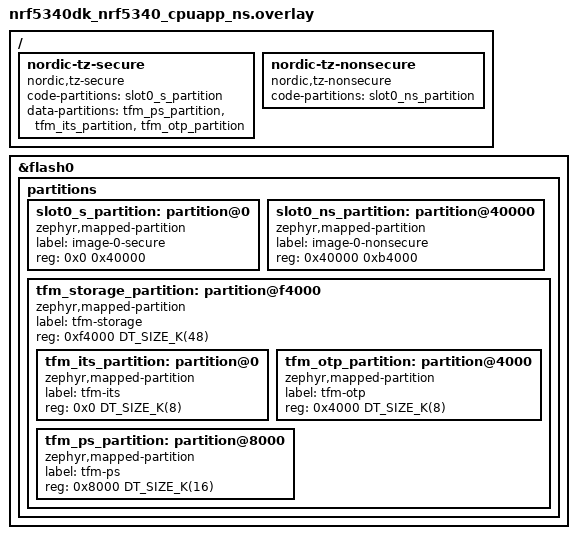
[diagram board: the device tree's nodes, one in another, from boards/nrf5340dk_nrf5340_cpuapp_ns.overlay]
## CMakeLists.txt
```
#
# Copyright (c) 2021 Nordic Semiconductor ASA
#
# SPDX-License-Identifier: LicenseRef-Nordic-5-Clause
#

cmake_minimum_required(VERSION 3.20.0)

find_package(Zephyr REQUIRED HINTS $ENV{ZEPHYR_BASE})
project(NONE)

FILE(GLOB app_sources src/*.c)
target_sources(app PRIVATE ${app_sources})

if(DEFINED CONFIG_SOC_NRF9160)
  set(family_arg NRF91)
else()
  set(family_arg NRF53)
endif()


if("${CONFIG_HUK_TEST_BOARD_SNR}" STREQUAL "")
  message(WARNING "If it is to be run on target, this test requires setting "
    "CONFIG_HUK_TEST_BOARD_SNR")
else()
  add_custom_command(TARGET app
    POST_BUILD
    COMMAND
    ${PYTHON_EXECUTABLE}
    ${CMAKE_CURRENT_LIST_DIR}/write_kmu.py
    --family ${family_arg}
    --snr ${CONFIG_HUK_TEST_BOARD_SNR}
    )
endif()
```

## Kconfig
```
#
# Copyright (c) 2021 Nordic Semiconductor
#
# SPDX-License-Identifier: LicenseRef-Nordic-5-Clause
#

source "Kconfig.zephyr"

config HUK_TEST_BOARD_SNR
	string "Segger ID of the board to flash KMU values to"
	help
	  This must be the same board as will be flashed with west flash
	  later. The flashing of KMU happens during the build stage, so
	  west flash must be called without --erase as to not erase the KMU.
```

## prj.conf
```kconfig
#
# Copyright (c) 2021-2023 Nordic Semiconductor ASA
#
# SPDX-License-Identifier: LicenseRef-Nordic-5-Clause
#

CONFIG_ZTEST=y
CONFIG_BOOTLOADER_MCUBOOT=n

CONFIG_PSA_CRYPTO=y
CONFIG_PSA_WANT_ALG_HKDF=y
CONFIG_PSA_WANT_ALG_SHA_256=y
```

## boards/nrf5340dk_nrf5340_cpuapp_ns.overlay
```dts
/*
 * Copyright (c) 2026 Nordic Semiconductor ASA
 *
 * SPDX-License-Identifier: LicenseRef-Nordic-5-Clause
 */

/delete-node/ &boot_partition;
/delete-node/ &slot0_partition;
/delete-node/ &slot1_partition;
/delete-node/ &storage_partition;

/delete-node/ &tfm_its_partition;
/delete-node/ &tfm_otp_partition;
/delete-node/ &tfm_ps_partition;

&flash0 {
	partitions {
		slot0_s_partition: partition@0 {
			compatible = "zephyr,mapped-partition";
			label = "image-0-secure";
			reg = <0x0 0x40000>;
		};

		slot0_ns_partition: partition@40000 {
			compatible = "zephyr,mapped-partition";
			label = "image-0-nonsecure";
			reg = <0x40000 0xb4000>;
		};

		tfm_storage_partition: partition@f4000 {
			compatible = "zephyr,mapped-partition";
			label = "tfm-storage";
			reg = <0xf4000 DT_SIZE_K(48)>;
			ranges = <0x0 0xf4000 DT_SIZE_K(48)>;
			#address-cells = <1>;
			#size-cells = <1>;

			tfm_its_partition: partition@0 {
				compatible = "zephyr,mapped-partition";
				label = "tfm-its";
				reg = <0x0 DT_SIZE_K(8)>;
			};

			tfm_otp_partition: partition@4000 {
				compatible = "zephyr,mapped-partition";
				label = "tfm-otp";
				reg = <0x4000 DT_SIZE_K(8)>;
			};

			tfm_ps_partition: partition@8000 {
				compatible = "zephyr,mapped-partition";
				label = "tfm-ps";
				reg = <0x8000 DT_SIZE_K(16)>;
			};
		};
	};
};

/ {
	/delete-node/ nordic-tz-secure;
	/delete-node/ nordic-tz-nonsecure;

	nordic-tz-secure {
		compatible = "nordic,tz-secure";
		code-partitions = <&slot0_s_partition>;
		data-partitions = <&tfm_ps_partition>,
				  <&tfm_its_partition>,
				  <&tfm_otp_partition>;
	};

	nordic-tz-nonsecure {
		compatible = "nordic,tz-nonsecure";
		code-partitions = <&slot0_ns_partition>;
	};
};
```

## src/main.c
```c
/*
 * Copyright (c) 2021 Nordic Semiconductor ASA
 *
 * SPDX-License-Identifier: LicenseRef-Nordic-5-Clause
 */

#include <zephyr/ztest.h>
#include <psa/crypto.h>
#include <tfm_crypto_defs.h>

#if defined(CONFIG_HAS_HW_NRF_CC312)
__ALIGNED(4)
static uint8_t test_label[16] = {
	0xe2, 0x75, 0xab, 0x25, 0x00, 0x3b, 0x15, 0xe1,
	0xa1, 0x98, 0x78, 0x5b, 0x4e, 0x57, 0x43, 0x9a
};

__ALIGNED(4)
static uint8_t expected_key[32] = {
	0xa9, 0x4d, 0x17, 0x7f, 0x5b, 0x6a, 0xc4, 0x6e,
	0x64, 0xe1, 0xae, 0xdb, 0x93, 0xee, 0x8a, 0xec,
	0x47, 0x70, 0x9a, 0x40, 0xeb, 0xb2, 0xc2, 0x66,
	0x4f, 0xfe, 0x5b, 0x25, 0x2b, 0x09, 0xd4, 0x75
};
#else
__ALIGNED(4)
static uint8_t test_label[19] = {
	0x29, 0xd6, 0xa6, 0x8d, 0x3f, 0xfb, 0x39, 0x1f,
	0x03, 0x6d, 0xd5, 0x3b, 0xe3, 0x54, 0xe4, 0x02,
	0x9a, 0x69, 0x5a
};

__ALIGNED(4)
static uint8_t expected_key[16] = {
	0x75, 0x70, 0xca, 0xb8, 0x88, 0x6d, 0xcc, 0x91,
	0x9a, 0xfe, 0xfc, 0x34, 0xf1, 0xc1, 0xc5, 0xf5
};
#endif


ZTEST(test_hw_unique_key_tfm, test_hw_unique_key_tfm1)
{
#ifdef CONFIG_SOC_NRF5340_CPUAPP
	uint8_t out_key[32];
#else
	uint8_t out_key[16];
#endif
	uint32_t out_len;
	psa_key_id_t key_id = 1234;
	psa_status_t status;
	psa_key_attributes_t attributes = PSA_KEY_ATTRIBUTES_INIT;
	psa_key_derivation_operation_t op = PSA_KEY_DERIVATION_OPERATION_INIT;

	/* Set the key attributes for the storage key */
	psa_set_key_usage_flags(&attributes,
			(PSA_KEY_USAGE_ENCRYPT | PSA_KEY_USAGE_DECRYPT | PSA_KEY_USAGE_EXPORT));
	psa_set_key_algorithm(&attributes, PSA_ALG_AEAD_WITH_SHORTENED_TAG(PSA_ALG_CMAC, 16));
	psa_set_key_type(&attributes, PSA_KEY_TYPE_AES);
	psa_set_key_bits(&attributes, sizeof(out_key) * 8);

	status = psa_key_derivation_setup(&op, PSA_ALG_HKDF(PSA_ALG_SHA_256));
	zassert_equal(PSA_SUCCESS, status, "status %d != PSA_SUCCESS\r\n", status);

	/* Set up a key derivation operation with HUK  */
	status = psa_key_derivation_input_key(&op, PSA_KEY_DERIVATION_INPUT_SECRET,
					      TFM_BUILTIN_KEY_ID_HUK);

	/* Supply the PS key label as an input to the key derivation */
	status = psa_key_derivation_input_bytes(&op, PSA_KEY_DERIVATION_INPUT_INFO,
						test_label,
						sizeof(test_label));
	zassert_equal(PSA_SUCCESS, status, "psa_key_derivation_input_bytes failed: %d\n", status);

	/* Create the storage key from the key derivation operation */
	status = psa_key_derivation_output_key(&attributes, &op, &key_id);
	zassert_equal(PSA_SUCCESS, status, "psa_key_derivation_output_key failed: %d\n", status);

	/* Free resources associated with the key derivation operation */
	status = psa_key_derivation_abort(&op);
	zassert_equal(PSA_SUCCESS, status, NULL);

	status = psa_export_key(key_id, out_key, sizeof(out_key), &out_len);
	zassert_equal(PSA_SUCCESS, status, NULL);
	zassert_equal(out_len, sizeof(out_key), NULL);

	for (int i = 0; i < sizeof(expected_key); i++) {
		printk("%02x ", out_key[i]);
	}
	printk("\r\n");

	zassert_mem_equal(expected_key, out_key, sizeof(expected_key), NULL);
}

ZTEST_SUITE(test_hw_unique_key_tfm, NULL, NULL, NULL, NULL, NULL);
```
